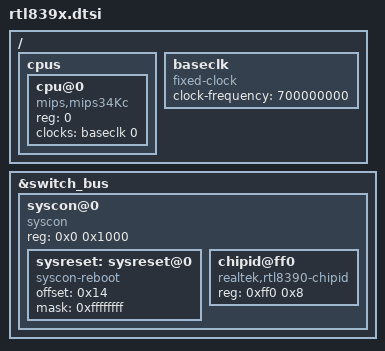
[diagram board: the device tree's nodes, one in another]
// SPDX-License-Identifier: GPL-2.0-or-later OR BSD-2-Clause

/ {
	cpus {
		#address-cells = <1>;
		#size-cells = <0>;

		cpu@0 {
			compatible = "mips,mips34Kc";
			reg = <0>;
			clocks = <&baseclk 0>;
			clock-names = "cpu";
		};
	};

	baseclk: baseclk {
		compatible = "fixed-clock";
		#clock-cells = <0>;
		clock-frequency = <700000000>;
	};
};

&switch_bus {
	syscon@0 {
		compatible = "syscon", "simple-mfd";
		reg = <0x0 0x1000>;

		sysreset: sysreset@0 {
			compatible = "syscon-reboot";
			offset = <0x14>;
			mask = <0xffffffff>;
		};

		chipid@ff0 {
			compatible = "realtek,rtl8390-chipid";
			reg = <0xff0 0x8>;
		};
	};
};
